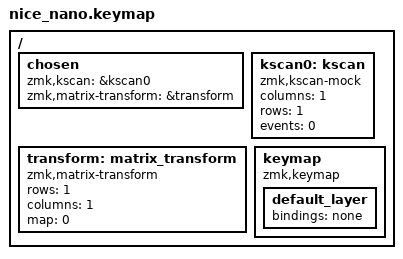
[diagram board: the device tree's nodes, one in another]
#include <behaviors.dtsi>
#include <dt-bindings/zmk/keys.h>

/ {
    chosen {
        zmk,kscan = &kscan0;
        zmk,matrix-transform = &transform;
    };

    kscan0: kscan {
        compatible = "zmk,kscan-mock";
        columns = <1>;
        rows = <1>;
        events = <0>;
    };

    transform: matrix_transform {
        compatible = "zmk,matrix-transform";
        rows = <1>;
        columns = <1>;
        /* Use a raw position; RC() can collide with modifiers.h */
        map = <0>;
    };

    keymap {
        compatible = "zmk,keymap";

        default_layer {
            bindings = <
                &none
            >;
        };
    };
};
